# HSM_HSM_SHA_CE004000h register map
Vendor: Texas Instruments
Peripheral module from a debugger description file (folder AM263X).
Registers are 32-bit, read-write, reset values left out (the file's numbers can be read two ways) unless marked. A register's access mark holds for its fields unless they carry their own. Offsets are as the file gives them; lines under a group give offsets from that group; [hi:lo] are bit positions; {n}, {i} and the like mark numbered series; 'fields as' and 'values as' point back to an identical list; <NAME> marks a mode.

## HSM_SHA
0x00 HSM_SHA_S_ODIGEST_A — WRITE: Outer Digest [127:96] for MD5 [159:128] for SHA-1 [255:224] for SHA-2 / HMAC Key [31:0] for HMAC key proc READ: Outer Digest [127:96] for MD5 [159:128] for SHA-1 [255:224] for SHA-2
  [31:0] DATA
0x04 HSM_SHA_S_ODIGEST_B — WRITE: Outer Digest [95:64] for MD5 [127:96] for SHA-1 [223:192] for SHA-2 / HMAC Key [63:32] for HMAC key proc READ: Outer Digest [95:64] for MD5 [127:96] for SHA-1 [223:192] for SHA-2
  [31:0] DATA
0x08 HSM_SHA_S_ODIGEST_C — WRITE: Outer Digest [63:32] for MD5 [95:64] for SHA-1 [191:160] for SHA-2 / HMAC Key [95:64] for HMAC key proc READ: Outer Digest [63:32] for MD5 [95:64] for SHA-1 [191:160] for SHA-2
  [31:0] DATA
0x0C HSM_SHA_S_ODIGEST_D — WRITE: Outer Digest [31:0] for MD5 [63:31] for SHA-1 [159:128] for SHA-2 / HMAC Key [127:96] for HMAC key proc READ: Outer Digest [31:0] for MD5 [63:32] for SHA-1 [159:128] for SHA-2
  [31:0] DATA
0x10 HSM_SHA_S_ODIGEST_E — WRITE: Outer Digest [31:0] for SHA-1 [127:96] for SHA-2 / HMAC Key [159:128] for HMAC key proc READ: Outer Digest [31:0] for SHA-1 [127:96] for SHA-2
  [31:0] DATA
0x14 HSM_SHA_S_ODIGEST_F — WRITE: Outer Digest [95:64] for SHA-2 / HMAC Key [191:160] for HMAC key proc READ: Outer Digest [95:64] for SHA-2
  [31:0] DATA
0x18 HSM_SHA_S_ODIGEST_G — WRITE: Outer Digest [63:32] for SHA-2 / HMAC Key [223:192] for HMAC key proc READ: Outer Digest [63:32] for SHA-2
  [31:0] DATA
0x1C HSM_SHA_S_ODIGEST_H — WRITE: Outer Digest [31:0] for SHA-2 / HMAC Key [255:224] for HMAC key proc READ: Outer Digest [31:0] for SHA-2
  [31:0] DATA
0x20 HSM_SHA_S_IDIGEST_A — WRITE: Inner / Initial Digest [127:96] for MD5 [159:128] for SHA-1 [255:224] for SHA-2 / HMAC Key [287:256] for HMAC key proc READ: Intermediate / Inner Digest [127:96] for MD5 [159:128] for SHA-1 [255:224] for SHA-2 / Result Digest/MAC [127:96] for MD5 [159:128] for SHA-1 [223:192] for SHA-2 224 [255:224] for SHA-2 256.
  [31:0] DATA
0x24 HSM_SHA_S_IDIGEST_B — WRITE: Inner / Initial Digest [95:64] for MD5 [127:96] for SHA-1 [223:192] for SHA-2 / HMAC Key [319:288] for HMAC key proc READ: Intermediate / Inner Digest [95:64] for MD5 [127:96] for SHA-1 [223:192] for SHA-2 / Result Digest/MAC [95:64] for MD5 [127:96] for SHA-1 [191:160] for SHA-2 224 [223:192] for SHA-2 256.
  [31:0] DATA
0x28 HSM_SHA_S_IDIGEST_C — WRITE: Inner / Initial Digest [63:32] for MD5 [95:64] for SHA-1 [191:160] for SHA- 2 / HMAC Key [351:320] for HMAC key proc READ: Intermediate / Inner Digest [63:32] for MD5 [95:64] for SHA-1 [191:160] for SHA-2 / Result Digest/MAC [63:32] for MD5 [95:64] for SHA-1 [159:128] for SHA-2 224 [191:160] for SHA-2 256.
  [31:0] DATA
0x2C HSM_SHA_S_IDIGEST_D — WRITE: Inner / Initial Digest [31:0] for MD5 [63:32] for SHA-1 [159:128] for SHA-2 / HMAC Key [383:352] for HMAC key proc READ: Intermediate / Inner Digest [31:0] for MD5 [63:32] for SHA-1 [159:128] for SHA-2 / Result Digest/MAC [31:0] for MD5 [63:32] for SHA-1 [127:96] for SHA-2 224 [159:128] for SHA-2 256.
  [31:0] DATA
0x30 HSM_SHA_S_IDIGEST_E — WRITE: Inner / Initial Digest [31:0] for SHA-1 [127:96] for SHA-2 / HMAC Key [415:384] for HMAC key proc READ: Intermediate / Inner Digest [31:0] for SHA-1 [127:96] for SHA-2 / Result Digest/MAC [31:0] for SHA-1 [95:64] for SHA-2 224 [127:96] for SHA-2 256.
  [31:0] DATA
0x34 HSM_SHA_S_IDIGEST_F — WRITE: Inner / Initial Digest [95:64] for SHA-2 / HMAC Key [447:416] for HMAC key proc READ: Intermediate / Inner Digest [95:64] for SHA-2 / Result Digest/MAC [63:32] for SHA-2 224 [95:64] for SHA-2 256.
  [31:0] DATA
0x38 HSM_SHA_S_IDIGEST_G — WRITE: Inner / Initial Digest [63:32] for SHA-2 / HMAC Key [479:448] for HMAC key proc READ: Intermediate / Inner Digest [63:32] for SHA-2 / Result Digest/MAC [31:0] for SHA-2 224 [63:32] for SHA-2 256.
  [31:0] DATA
0x3C HSM_SHA_S_IDIGEST_H — WRITE: Inner / Initial Digest [31:0] for SHA-2 / HMAC Key [511:480] for HMAC key proc READ: Intermediate / Inner Digest [31:0] for SHA-2 / Result Digest/MAC [31:0] for SHA-2 256.
  [31:0] DATA
0x40 HSM_SHA_S_DIGEST_COUNT — WRITE: Initial Digest Count ([31:6] only [5:0] assumed 0) READ: Result / IntermediateDigest Count The initial digest byte count for hash/HMAC continue operations (HMAC Key Processing = 0 and Use Algorithm Constants = 0) on the Secure World must be written to this register prior to starting the operation by writing to S_HASH_MODE. When either HMAC Key Processing is 1 or Use Algorithm Constants is 1 this register does not need to be written it will be overwritten with 64 (1 hash block of key XOR ipad) or 0 respectively automatically. When starting a HMAC operation from pre-computes (HMAC Key Processing is 0) then the value 64 must be written here to compensate for the appended key XOR ipad block. Note that the value written should always be a 64 byte multiple the lower 6 bits written are ignored. The updated digest byte count (initial digest byte count + bytes processed) can be read from this register when the status register indicates that the operation is done or suspended due to a context switch request or when a Secure World context out DMA is requested. In Advanced DMA mode when not suspended with a partial result reading the SHA_P_DIGEST_COUNT register triggers the Hash/HMAC Engine to start the next context input DMA. Therefore reading the SHA_P_DIGEST_COUNT register should always be the last context-read action if not suspended with a partial result (i.e. PartHashReady interrupt not pending).
  [31:0] DATA
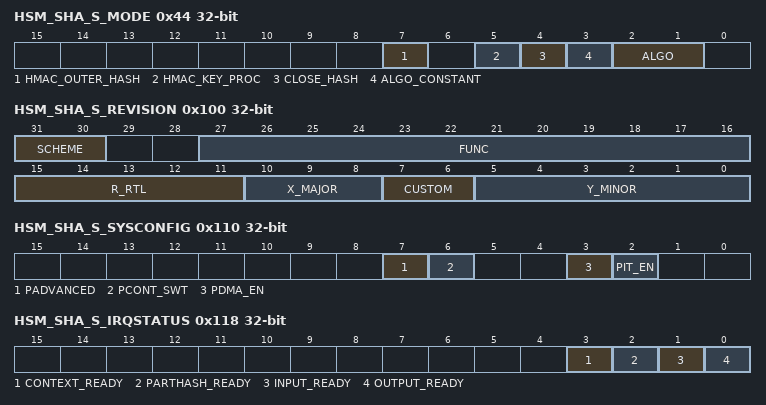
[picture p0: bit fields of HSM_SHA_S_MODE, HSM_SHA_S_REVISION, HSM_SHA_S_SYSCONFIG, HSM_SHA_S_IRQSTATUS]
0x44 HSM_SHA_S_MODE — Register SHA_MODE.
  [7] HMAC_OUTER_HASH — The HMAC Outer Hash is performed on the hash digest when the inner hash hash finished [block length exhausted and final hash performed if close_hash is 1]. This bit should normally be set together with close_hash to finish the inner hash first or Block Length should be zero [HMAC continue with the just outer hash to be done]. Auto cleared internally when outer hash performed. 0 No operation 1 hmac processing
  [5] HMAC_KEY_PROC — Performs HMAC key processing on the 512 bit HMAC key loaded into the SHA_P_IDIGEST_{A to H} and SHA_P_ODIGEST_{A to H} register block. Once HMAC key processing is finished this bit is automatically cleared and the resulting Inner and Outer digest is available from SHA_P_IDIGEST_{A to H} and SHA_P_ODIGEST_{A to H} respectively after which regular hash processing [using SHA_P_IDIGEST_{A to H} as initial digest] will commence until the Block Length is exhausted. 0 No operation. 1 Hmac processing.
  [4] CLOSE_HASH — Performs the padding the hash/HMAC will be 'closed' at the end of the block as per MD5/SHA-1/SHA-2 specification [i.e. appropriate padding is added] or no padding is done allowing the hash to be continued later. However if the hash/HMAC is not closed then the Block Length MUST be a multiple of 64 bytes to ensure correct operation. Auto cleared internally when hash closed. 0 No padding hash computation can be contimued. 1 Last packet will be padded.
  [3] ALGO_CONSTANT — The initial digest register will be overwritten with the algorithm constants for the selected algorithm when hashing and the initial digest count register will be reset to 0. This will start a normal hash operation. When continuing an existing hash or when performing an HMAC operation this register must be set to 0 and the intermediate/inner digest or HMAC key and digest count need to be written to the context input registers prior to Writing SHA_P_MODE. Auto cleared internally after first block processed. 0 Use pre-calculated digest [from an other operation] 1 Use constants of the selected algo.
  [2:1] ALGO — These bits select the hash algorithm to be used for processing: 0 md5_128 algorithm 0x1 sha1_160 algorithm 0x2 sha2_224 algorithm 0x3 sha2_256 algorithm
0x48 HSM_SHA_S_LENGTH — WRITE: Block Length / Remaining Byte Count (bytes) READ: Remaining Byte Count. The value programmed MUST be a 64-byte multiple if Close Hash is set to 0. This register is also the trigger to start processing: once this register is written the core will commence requesting input data via DMA or IRQ (if programmed length > 0) and start processing. The remaining byte count for the active operation can be read from this register when the interrupt status register indicates that the operation is suspended due to a context switch request.
  [31:0] DATA
{0x80+4i} HSM_SHA_S_DATA{i}_IN wo (i=0..9) — Data input message {i}
  [31:0] DATA{i}_IN — data
{0x80+4i} HSM_SHA_S_DATA{i}_IN wo (i=10..15) — Data input message {i}.
  [31:0] DATA{i}_IN — data
0x100 HSM_SHA_S_REVISION ro — Register SHA_REV.
  [31:30] SCHEME — Used to distinguish between old scheme and current. Read 0 Legacy ASP or WTBU scheme Read 0x1 Highlander 0.8 scheme
  [27:16] FUNC — Function indicates a software compatible module family. If there is no level of software compatibility a new Func number [and hence REVISION] should be assigned.
  [15:11] R_RTL — RTL Version [R] maintained by IP design owner. RTL follows a numbering such as X.Y.R.Z which are explained in this table. R changes ONLY when: [1] PDS uploads occur which may have been due to spec changes [2] Bug fixes occur [3] Resets to '0' when X or Y changes. Design team has an internal 'Z' [customer invisible] number which increments on every drop that happens due to DV and RTL updates. Z resets to 0 when R increments.
  [10:8] X_MAJOR — Major Revision [X] maintained by IP specification owner. X changes ONLY when: [1] There is a major feature addition. An example would be adding Master Mode to Utopia Level2. The Func field [or Class/Type in old PID format] will remain the same. X does NOT change due to: [1] Bug fixes [2] Change in feature parameters.
  [7:6] CUSTOM — Indicates a special version for a particular device. Consequence of use may avoid use of standard Chip Support Library [CSL] / Drivers. Read 0 Non custom [standard] revision
  [5:0] Y_MINOR — Minor Revision [Y] maintained by IP specification owner. Y changes ONLY when: [1] Features are scaled [up or down]. Flexibility exists in that this feature scalability may either be represented in the Y change or a specific register in the IP that indicates which features are exactly available. [2] When feature creeps from Is-Not list to Is list. But this may not be the case once it sees silicon; in which case X will change. Y does NOT change due to: [1] Bug fixes [2] Typos or clarifications [3] major functional/feature change/addition/deletion. Instead these changes may be reflected via R S X as applicable. Spec owner maintains a customer-invisible number 'S' which changes due to: [1] Typos/clarifications [2] Bug documentation. Note that this bug is not due to a spec change but due to implementation. Nevertheless the spec tracks the IP bugs. An RTL release [say for silicon PG1.1] that occurs due to bug fix should document the corresponding spec number [X.Y.S] in its release notes.
0x110 HSM_SHA_S_SYSCONFIG — Register SHA_SYSCONFIG.
  [7] PADVANCED — If set to 1 Advanced mode is enabled for the Secure World. If set to 0 Legacy mode is enabled for the Secure World.
  [6] PCONT_SWT — Finish all pending data and context DMA input requests [but will not assert any new requests] finish processing all data in the module and provide a saved context [partial hash result updated digest count remaining length updated mode information where applicable] for the last operation that was interrupted so that it can be resumed later.
  [3] PDMA_EN — Enable dma Read 0 Interrupt disenabled Read 1 Interrupt enabled
  [2] PIT_EN — Enable interrupt Read 0 Interrupt disenabled Read 1 Interrupt enabled
0x114 HSM_SHA_S_SYSSTATUS — Register SHA_SYSSTATUS.
  [0] RESETDONE — data
0x118 HSM_SHA_S_IRQSTATUS ro — Register SHA_IRQSTATUS.
  [3] CONTEXT_READY — Indicates that the secure side context input registers are available for a new context for the next packet to be processed.
  [2] PARTHASH_READY — After a secure side context switch request this bit will read as 1 indicating that the saved context is available from the secure side context output registers. Note that if the context switch request coincides with a final hash [when hashing] or an outer hash [when doing HMAC] that PartHashReady will not become active but a regular Output Ready will occur instead [indicating that the result is final and therefore no continuation is required].
  [1] INPUT_READY — Indicates that the secure side data FIFO is ready to receive the next 64 byte data block.
  [0] OUTPUT_READY — Indicates that a [partial] result or saved context is available from the secure side context output registers.
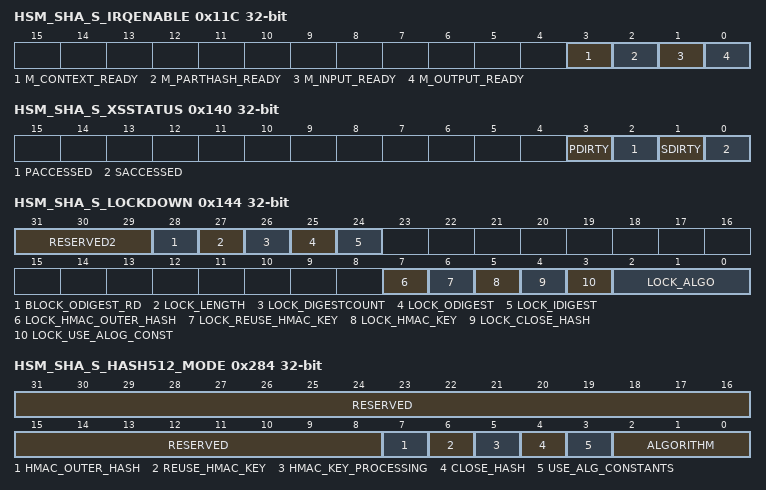
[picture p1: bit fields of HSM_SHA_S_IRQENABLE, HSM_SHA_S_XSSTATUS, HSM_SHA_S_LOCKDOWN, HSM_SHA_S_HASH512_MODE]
0x11C HSM_SHA_S_IRQENABLE — Register SHA_IRQENABLE. The SHA_P_IRQENABLE register contains an enable bit for each unique interrupt for the public side. An interrupt is enabled when both the global enable in SHA_P_SYSCONFIG (PIT_en) and the bit in this register are both set to 1. An interrupt that is enabled is propagated to the SINTREQUEST_P output. Please note that the dedicated partial hash output (SINTREQUEST_PART_P) is not affected by this register it is only affected by the global enable SHA_P_SYSCONFIG (PIT_en).
  [3] M_CONTEXT_READY — mask for context ready
  [2] M_PARTHASH_READY — mask for partial hash
  [1] M_INPUT_READY — mask for input_ready
  [0] M_OUTPUT_READY — mask for output_ready
0x140 HSM_SHA_S_XSSTATUS — Secure/Private world Register read/write status.
  [3] PDIRTY — This bit is set to 1 by the module if any of the Public World registers is written. It can be cleared by the host by Writing a 1 in this location.
  [2] PACCESSED — This bit is set to 1 by the module if any of the Public World registers is read. It can be cleared by the host by Writing a 1 in this location
  [1] SDIRTY — This bit is set to 1 by the module if any of the Secure World registers is written. It can be cleared by the host by Writing a 1 in this location.
  [0] SACCESSED — This bit is set to 1 by the module if any of the Secure World registers is read. It can be cleared by the host by Writing a 1 in this location.
0x144 HSM_SHA_S_LOCKDOWN access per field — Use this Register to lock the algorithm preventing further use.
  [31:29] RESERVED2 ro — These bits should be written with zeroes and ignored on reads.
  [28] BLOCK_ODIGEST_RD rw — This makes the P_HASH_ODIGEST_A through P_HASH_ODIGEST_H write-only, further protecting the HMAC key from being read by Public World software. Note: setting this bit also makes HMAC continue operations impossible!
  [27] LOCK_LENGTH rw — When this bit is set, the P_HASH_LENGTH register cannot be overwritten. This prevents Public World software from truncating or extending the block to be hashed or starting hash/HMAC operations by itself.
  [26] LOCK_DIGESTCOUNT rw — When this bit is set, the P_HASH_DIGEST_COUNT register cannot be overwritten. This, in combination with bits 3 and 24 prevents the Public World software from adding data at the front of the block to be hashed.
  [25] LOCK_ODIGEST rw — When this bit is set, the P_HASH_ODIGEST_A through P_HASH_ODIGEST_H registers cannot be overwritten. This prevents Public World software from loading a weak and/or known HMAC key or an outer digest value.
  [24] LOCK_IDIGEST rw — When this bit is set, the P_HASH_IDIGEST_A through P_HASH_IDIGEST_H registers cannot be overwritten. This prevents Public World software from loading a weak and/or known key or an initial digest value
  [7] LOCK_HMAC_OUTER_HASH rw — When this bit is set, HMAC Outer Hash bit in P_HASH_MODE cannot be modified.This prevents Public World software from bypassing the HMAC closure by clearing the corresponding mode bit during processing.
  [6] LOCK_REUSE_HMAC_KEY rw — When this bit is set, the Reuse HMAC Key bit in P_HASH_MODE cannot be modified
  [5] LOCK_HMAC_KEY rw — When this bit is set, the HMAC Key Preprocessing bit in P_HASH_MODE cannot be modified. This prevents Public World software from bypassing the HMAC key preprocessing step and using the key data directly
  [4] LOCK_CLOSE_HASH rw — When this bit is set, the Close Hash bit in P_HASH_MODE cannot be modified.This prevents Public World software from bypassing the hash closure by clearing the corresponding mode bit during processing.
  [3] LOCK_USE_ALOG_CONST rw — When this bit is set, the Use Alg Constants bit in P_HASH_MODE cannot be modified. This e.g. prevents Public World software from switching to [known!] algorithm constants instead of the [secret key based?] loaded & locked initial digest.
  [2:0] LOCK_ALGO rw — When either lock bit is set, the corresponding Algorithm bit in P_HASH_MODE cannot be modified. This locks the algorithm preventing further use.
0x200 HSM_SHA_S_HASH512_ODIGEST_A — Public World Outer SHA-512 Digest .
  [31:0] ODIGEST_A — W: Outer Digest [511:480] for SHA-384 and SHA-512 / SHA512_HMAC Key [31:0] for HMAC key procR: Outer Digest [511:480] for SHA-384 and SHA-512
0x204 HSM_SHA_S_HASH512_ODIGEST_B — Public World Outer SHA-512 Digest .
  [31:0] ODIGEST_B — W: Outer Digest [479:448] for SHA-384 and SHA-512 / SHA512_HMAC Key [63:32] for HMAC key procR: Outer Digest [479:448] for SHA-384 and SHA-512
0x208 HSM_SHA_S_HASH512_ODIGEST_C — Public World Outer SHA-512 Digest .
  [31:0] ODIGEST_C — W: Outer Digest [447:416] for SHA-384 and SHA-512 / SHA512_HMAC Key [95:64] for HMAC key procR: Outer Digest [447:416] for SHA-384 and SHA-512
0x20C HSM_SHA_S_HASH512_ODIGEST_D — Public World Outer SHA-512 Digest .
  [31:0] ODIGEST_D — W: Outer Digest [415:384] for SHA-384 and SHA-512 / SHA512_HMAC Key [127:96] for HMAC key procR: Outer Digest [415:384] for SHA-384 and SHA-512
0x210 HSM_SHA_S_HASH512_ODIGEST_E — Public World Outer SHA-512 Digest .
  [31:0] ODIGEST_E — W: Outer Digest [383:352] for SHA-384 and SHA-512 / SHA512_HMAC Key [159:128] for HMAC key procR: Outer Digest [383:352] for SHA-384 and SHA-512
0x214 HSM_SHA_S_HASH512_ODIGEST_F — Public World Outer SHA-512 Digest .
  [31:0] ODIGEST_F — W: Outer Digest [351:320] for SHA-384 and SHA-512 / SHA512_HMAC Key [191:160] for HMAC key procR: Outer Digest [351:320] for SHA-384 and SHA-512
0x218 HSM_SHA_S_HASH512_ODIGEST_G — Public World Outer SHA-512 Digest .
  [31:0] ODIGEST_G — W: Outer Digest [319:288] for SHA-384 and SHA-512 / SHA512_HMAC Key [223:192] for HMAC key procR: Outer Digest [319:288] for SHA-384 and SHA-512
0x21C HSM_SHA_S_HASH512_ODIGEST_H — Public World Outer SHA-512 Digest .
  [31:0] ODIGEST_H — W: Outer Digest [287:256] for SHA-384 and SHA-512 / SHA512_HMAC Key [255:244] for HMAC key procR: Outer Digest [287:256] for SHA-384 and SHA-512
0x220 HSM_SHA_S_HASH512_ODIGEST_I — Public World Outer SHA-512 Digest .
  [31:0] ODIGEST_I — W: Outer Digest [255:224] for SHA-384 and SHA-512 / SHA512_HMAC Key [287:256] for HMAC key procR: Outer Digest [255:224] for SHA-384 and SHA-512
0x224 HSM_SHA_S_HASH512_ODIGEST_J — Public World Outer SHA-512 Digest .
  [31:0] ODIGEST_J — W: Outer Digest [223:192] for SHA-384 and SHA-512 / SHA512_HMAC Key [319:288] for HMAC key procR: Outer Digest [223:129] for SHA-384 and SHA-512
0x228 HSM_SHA_S_HASH512_ODIGEST_K — Public World Outer SHA-512 Digest .
  [31:0] ODIGEST_K — W: Outer Digest [191:160] for SHA-384 and SHA-512 / SHA512_HMAC Key [351:320] for HMAC key procR: Outer Digest [191:160] for SHA-384 and SHA-512
0x22C HSM_SHA_S_HASH512_ODIGEST_L — Public World Outer SHA-512 Digest .
  [31:0] ODIGEST_L — W: Outer Digest [159:128] for SHA-384 and SHA-512 / SHA512_HMAC Key [383:352] for HMAC key procR: Outer Digest [159:128] for SHA-384 and SHA-512
0x230 HSM_SHA_S_HASH512_ODIGEST_M — Public World Outer SHA-512 Digest .
  [31:0] ODIGEST_M — W: Outer Digest [128:96] for SHA-384 and SHA-512 / SHA512_HMAC Key [415:384] for HMAC key procR: Outer Digest [128:96] for SHA-384 and SHA-512
0x234 HSM_SHA_S_HASH512_ODIGEST_N — Public World Outer SHA-512 Digest .
  [31:0] ODIGEST_N — W: Outer Digest [95:64] for SHA-384 and SHA-512 / SHA512_HMAC Key [447:416] for HMAC key procR: Outer Digest [95:64] for SHA-384 and SHA-512
0x238 HSM_SHA_S_HASH512_ODIGEST_O — Public World Outer SHA-512 Digest .
  [31:0] ODIGEST_O — W: Outer Digest [63:32] for SHA-384 and SHA-512 / SHA512_HMAC Key [479:448] for HMAC key procR: Outer Digest [63:32] for SHA-384 and SHA-512
0x23C HSM_SHA_S_HASH512_ODIGEST_P — Public World Outer SHA-512 Digest .
  [31:0] ODIGEST_P — W: Outer Digest [31:0] for SHA-384 and SHA-512 / SHA512_HMAC Key [511:480] for HMAC key procR: Outer Digest [31:0] for SHA-384 and SHA-512
0x240 HSM_SHA_S_HASH512_IDIGEST_A — Public World Inner SHA-512 Digest .
  [31:0] IDIGEST_A — W: Inner / Initial Digest [383:352] for SHA-384 and [511:480] for SHA-512 / SHA512_HMAC Key [543:512] for HMAC key procR: Intermediate / Inner Digest Digest [383:352] for SHA-384 and [511:480] for SHA-512Result Digest/MAC Digest [383:352] for SHA-384 and [511:480] for SHA-512
0x244 HSM_SHA_S_HASH512_IDIGEST_B — Public World Inner SHA-512 Digest .
  [31:0] IDIGEST_B — W: Inner / Initial Digest [531:320] for SHA-384 and [479:448] for SHA-512 / SHA512_HMAC Key [543:512] for HMAC key procR: Intermediate / Inner Digest Digest Digest [531:320] for SHA-384 and [479:448] for SHA-512Result Digest/MAC Digest Digest [531:320] for SHA-384 and [479:448] for SHA-512
0x248 HSM_SHA_S_HASH512_IDIGEST_C — Public World Inner SHA-512 Digest .
  [31:0] IDIGEST_C — W: Inner / Initial Digest [319:288] for SHA-384 and [416:447] for SHA-512 / SHA512_HMAC Key [543:512] for HMAC key procR: Intermediate / Inner Digest Digest Digest [319:288] for SHA-384 and [416:447] for SHA-512Result Digest/MAC Digest Digest [319:288] for SHA-384 and [416:447] for SHA-512
0x24C HSM_SHA_S_HASH512_IDIGEST_D — Public World Inner SHA-512 Digest .
  [31:0] IDIGEST_D — W: Inner / Initial Digest [287:256] for SHA-384 and [415:384] for SHA-512 / SHA512_HMAC Key [639:608] for HMAC key procR: Intermediate / Inner Digest [287:256] for SHA-384 and [415:384] for SHA-512Result Digest/MAC Digest Digest [287:256] for SHA-384 and [415:384] for SHA-512
0x250 HSM_SHA_S_HASH512_IDIGEST_E — Public World Inner SHA-512 Digest .
  [31:0] IDIGEST_E — W: Inner / Initial Digest [255:224] for SHA-384 and [383:362] for SHA-512 / SHA512_HMAC Key [671:640] for HMAC key procR: Intermediate / Inner Digest [255:224] for SHA-384 and [383:362] for SHA-512Result Digest/MAC Digest Digest [255:224] for SHA-384 and [383:362] for SHA-512
0x254 HSM_SHA_S_HASH512_IDIGEST_F — Public World Inner SHA-512 Digest .
  [31:0] IDIGEST_F — W: Inner / Initial Digest [223:192] for SHA-384 and [351:320] for SHA-512 / SHA512_HMAC Key [703:672] for HMAC key procR: Intermediate / Inner Digest [223:192] for SHA-384 and [351:320] for SHA-512Result Digest/MAC Digest Digest [223:192] for SHA-384 and [351:320] for SHA-512
0x258 HSM_SHA_S_HASH512_IDIGEST_G — Public World Inner SHA-512 Digest .
  [31:0] IDIGEST_G — W: Inner / Initial Digest [191:160] for SHA-384 and [319:288] for SHA-512 / SHA512_HMAC Key [735:704] for HMAC key procR: Intermediate / Inner Digest [191:160] for SHA-384 and [319:288] for SHA-512Result Digest/MAC Digest Digest [191:160] for SHA-384 and [319:288] for SHA-512
0x25C HSM_SHA_S_HASH512_IDIGEST_H — Public World Inner SHA-512 Digest .
  [31:0] IDIGEST_H — W: Inner / Initial Digest [159:128] for SHA-384 and [287:256] for SHA-512 / SHA512_HMAC Key [767:736] for HMAC key procR: Intermediate / Inner Digest [159:128] for SHA-384 and [287:256] for SHA-512Result Digest/MAC Digest Digest [159:128] for SHA-384 and [287:256] for SHA-512
0x260 HSM_SHA_S_HASH512_IDIGEST_I — Public World Inner SHA-512 Digest .
  [31:0] IDIGEST_I — W: Inner / Initial Digest [127:96] for SHA-384 and [255:224] for SHA-512 / SHA512_HMAC Key [799:768] for HMAC key procR: Intermediate / Inner Digest [127:96] for SHA-384 and [255:224] for SHA-512Result Digest/MAC Digest Digest [127:96] for SHA-384 and [255:224] for SHA-512
0x264 HSM_SHA_S_HASH512_IDIGEST_J — Public World Inner SHA-512 Digest .
  [31:0] IDIGEST_J — W: Inner / Initial Digest [95:64] for SHA-384 and [223:192] for SHA-512 / SHA512_HMAC Key [831:800] for HMAC key procR: Intermediate / Inner Digest [95:64] for SHA-384 and [223:192] for SHA-512Result Digest/MAC Digest Digest [95:64] for SHA-384 and [223:192] for SHA-512
0x268 HSM_SHA_S_HASH512_IDIGEST_K — Public World Inner SHA-512 Digest .
  [31:0] IDIGEST_K — W: Inner / Initial Digest [63:32] for SHA-384 and [191:160] for SHA-512 / SHA512_HMAC Key [863:832] for HMAC key procR: Intermediate / Inner Digest [63:32] for SHA-384 and [191:160] for SHA-512Result Digest/MAC Digest Digest [63:32] for SHA-384 and [191:160] for SHA-512
0x26C HSM_SHA_S_HASH512_IDIGEST_L — Public World Inner SHA-512 Digest .
  [31:0] IDIGEST_L — W: Inner / Initial Digest [31:0] for SHA-384 and [159:128] for SHA-512 / SHA512_HMAC Key [895:864] for HMAC key procR: Intermediate / Inner Digest [31:0] for SHA-384 and [159:128] for SHA-512Result Digest/MAC Digest Digest [31:0] for SHA-384 and [159:128] for SHA-512
0x270 HSM_SHA_S_HASH512_IDIGEST_M — Public World Inner SHA-512 Digest .
  [31:0] IDIGEST_M — W: Inner / Initial Digest [127:96] for SHA-512 / SHA512_HMAC Key [927:896] for HMAC key procR: Intermediate / Inner Digest [127:96] for SHA-512Result Digest/MAC Digest Digest [127:96] for SHA-512
0x274 HSM_SHA_S_HASH512_IDIGEST_N — Public World Inner SHA-512 Digest .
  [31:0] IDIGEST_N — W: Inner / Initial Digest [95:64] for SHA-512 / SHA512_HMAC Key [959:928] for HMAC key procR: Intermediate / Inner Digest [95:64] for SHA-512Result Digest/MAC Digest Digest [95:64] for SHA-512
0x278 HSM_SHA_S_HASH512_IDIGEST_O — Public World Inner SHA-512 Digest .
  [31:0] IDIGEST_O — W: Inner / Initial Digest [63:32] for SHA-512 / SHA512_HMAC Key [991:960] for HMAC key procR: Intermediate / Inner Digest [63:32] for SHA-512Result Digest/MAC Digest Digest [63:32] for SHA-512
0x27C HSM_SHA_S_HASH512_IDIGEST_P — Public World Inner SHA-512 Digest .
  [31:0] IDIGEST_P — W: Inner / Initial Digest [31:0] for SHA-512 / SHA512_HMAC Key 1023992] for HMAC key procR: Intermediate / Inner Digest [31:0] for SHA-512Result Digest/MAC Digest Digest [31:0] for SHA-512
0x280 HSM_SHA_S_HASH512_DIGEST_COUNT — Public World SHA-512 Digest Count .
  [31:0] DIGEST_COUNT — W: Initial Digest Count [[31:7] only, [6:0] assumed 0]R: Result / IntermediateDigest Count
0x284 HSM_SHA_S_HASH512_MODE access per field — Public World SHA-512 Hash Mode.
  [31:8] RESERVED ro — These bits should be written with zeroes and ignored on reads.
  [7] HMAC_OUTER_HASH rw — If set to 1, the HMAC Outer Hash is performed on the hash digest when the inner hash hash finished [block length exhausted and final hash performed if Close Hash is 1].This bit should normally be set together with Close Hash to finish the inner hash first, or Block Length should be zero [HMAC continue with the just outer hash to be done].Auto cleared internally when outer hash performed.
  [6] REUSE_HMAC_KEY rw — If set to 1, an HMAC operation is started using the HMAC key that was loaded at the time HMAC Key Processing was last performed, provided that the P_HASH512_ODIGEST registers have not been overwritten since. This makes it possible to authenticate multiple blocks using the HMAC key without actually having to reload the key.Note that P_HASH512_DIGEST_COUNT is forced to 128 to indicate that the 128 byte key XOR ipad block has been processed first. This bit should not be set together with bit 5.
  [5] HMAC_KEY_PROCESSING rw — If set to 1, the hash core will perform HMAC key processing on the HMAC key [with block size length] loaded into the P_HASH512_IDIGEST:P_HASH512_ODIGEST register block. Once HMAC key processing is finished, this bit is automatically cleared and the resulting Inner and Outer digest is available from P_HASH512_IDIGEST and P_HASH512_ODIGEST respectively, after which regular hash processing [using P_HASH512_IDIGEST as initial digest] will commence until the Block Length is exhausted. Note that P_HASH_DIGEST512_COUNT is forced to 128 to indicate that the 128 byte key XOR ipad block has been processed first.
  [4] CLOSE_HASH rw — If set to 1, then the hash/HMAC will be 'closed' at the end of the block, as per MD5/SHA-1/SHA-2 specification [i.e. appropriate padding is added]. If set to 0, then the hash/HMAC will not be closed and can be continued later. However, if the hash/HMAC is not closed then the Block Length MUST be a multiple of the hash bloc k size to ensure correct operation. Auto cleared internally when hash close operation starts.
  [3] USE_ALG_CONSTANTS rw — If set to 1, the initial digest register will be overwritten with the algorithm constants for the selected algorithm when hashing and the initial digest count register will be reset to 0. This will start a normal hash operation. When continuing an existing hash or when performing an HMAC operation, this register must be set to 0 and the intermediate/inner digest or HMAC key and digest count need to be written to the context input registers prior to Writing P_HASH512_MODE.Auto cleared internally after first block processed.
  [2:0] ALGORITHM rw — These bits select the hash algorithm to be used for processing:000 - MD5010 - SHA-1100 - SHA-224110 - SHA-256001 - SHA-384011 - SHA-512
0x288 HSM_SHA_S_HASH512_LENGTH — Public World SHA-512 Block Length .
  [31:0] LENGTH — W: Block Length / Remaining Byte Count [bytes]R: Remaining Byte Count
0x1000 HSM_SHA_P_ODIGEST_A — WRITE: Outer Digest [127:96] for MD5 [159:128] for SHA-1 [255:224] for SHA-2 / HMAC Key [31:0] for HMAC key proc READ: Outer Digest [127:96] for MD5 [159:128] for SHA-1 [255:224] for SHA-2
  [31:0] DATA
0x1004 HSM_SHA_P_ODIGEST_B — WRITE: Outer Digest [95:64] for MD5 [127:96] for SHA-1 [223:192] for SHA-2 / HMAC Key [63:32] for HMAC key proc READ: Outer Digest [95:64] for MD5 [127:96] for SHA-1 [223:192] for SHA-2
  [31:0] DATA
0x1008 HSM_SHA_P_ODIGEST_C — WRITE: Outer Digest [63:32] for MD5 [95:64] for SHA-1 [191:160] for SHA-2 / HMAC Key [95:64] for HMAC key proc READ: Outer Digest [63:32] for MD5 [95:64] for SHA-1 [191:160] for SHA-2
  [31:0] DATA
0x100C HSM_SHA_P_ODIGEST_D — WRITE: Outer Digest [31:0] for MD5 [63:31] for SHA-1 [159:128] for SHA-2 / HMAC Key [127:96] for HMAC key proc READ: Outer Digest [31:0] for MD5 [63:32] for SHA-1 [159:128] for SHA-2
  [31:0] DATA
0x1010 HSM_SHA_P_ODIGEST_E — WRITE: Outer Digest [31:0] for SHA-1 [127:96] for SHA-2 / HMAC Key [159:128] for HMAC key proc READ: Outer Digest [31:0] for SHA-1 [127:96] for SHA-2
  [31:0] DATA
0x1014 HSM_SHA_P_ODIGEST_F — WRITE: Outer Digest [95:64] for SHA-2 / HMAC Key [191:160] for HMAC key proc READ: Outer Digest [95:64] for SHA-2
  [31:0] DATA
0x1018 HSM_SHA_P_ODIGEST_G — WRITE: Outer Digest [63:32] for SHA-2 / HMAC Key [223:192] for HMAC key proc READ: Outer Digest [63:32] for SHA-2
  [31:0] DATA
0x101C HSM_SHA_P_ODIGEST_H — WRITE: Outer Digest [31:0] for SHA-2 / HMAC Key [255:224] for HMAC key proc READ: Outer Digest [31:0] for SHA-2
  [31:0] DATA
0x1020 HSM_SHA_P_IDIGEST_A — WRITE: Inner / Initial Digest [127:96] for MD5 [159:128] for SHA-1 [255:224] for SHA-2 / HMAC Key [287:256] for HMAC key proc READ: Intermediate / Inner Digest [127:96] for MD5 [159:128] for SHA-1 [255:224] for SHA-2 / Result Digest/MAC [127:96] for MD5 [159:128] for SHA-1 [223:192] for SHA-2 224 [255:224] for SHA-2 256.
  [31:0] DATA
0x1024 HSM_SHA_P_IDIGEST_B — WRITE: Inner / Initial Digest [95:64] for MD5 [127:96] for SHA-1 [223:192] for SHA-2 / HMAC Key [319:288] for HMAC key proc READ: Intermediate / Inner Digest [95:64] for MD5 [127:96] for SHA-1 [223:192] for SHA-2 / Result Digest/MAC [95:64] for MD5 [127:96] for SHA-1 [191:160] for SHA-2 224 [223:192] for SHA-2 256.
  [31:0] DATA
0x1028 HSM_SHA_P_IDIGEST_C — WRITE: Inner / Initial Digest [63:32] for MD5 [95:64] for SHA-1 [191:160] for SHA- 2 / HMAC Key [351:320] for HMAC key proc READ: Intermediate / Inner Digest [63:32] for MD5 [95:64] for SHA-1 [191:160] for SHA-2 / Result Digest/MAC [63:32] for MD5 [95:64] for SHA-1 [159:128] for SHA-2 224 [191:160] for SHA-2 256.
  [31:0] DATA
0x102C HSM_SHA_P_IDIGEST_D — WRITE: Inner / Initial Digest [31:0] for MD5 [63:32] for SHA-1 [159:128] for SHA-2 / HMAC Key [383:352] for HMAC key proc READ: Intermediate / Inner Digest [31:0] for MD5 [63:32] for SHA-1 [159:128] for SHA-2 / Result Digest/MAC [31:0] for MD5 [63:32] for SHA-1 [127:96] for SHA-2 224 [159:128] for SHA-2 256.
  [31:0] DATA
0x1030 HSM_SHA_P_IDIGEST_E — WRITE: Inner / Initial Digest [31:0] for SHA-1 [127:96] for SHA-2 / HMAC Key [415:384] for HMAC key proc READ: Intermediate / Inner Digest [31:0] for SHA-1 [127:96] for SHA-2 / Result Digest/MAC [31:0] for SHA-1 [95:64] for SHA-2 224 [127:96] for SHA-2 256.
  [31:0] DATA
0x1034 HSM_SHA_P_IDIGEST_F — WRITE: Inner / Initial Digest [95:64] for SHA-2 / HMAC Key [447:416] for HMAC key proc READ: Intermediate / Inner Digest [95:64] for SHA-2 / Result Digest/MAC [63:32] for SHA-2 224 [95:64] for SHA-2 256.
  [31:0] DATA
0x1038 HSM_SHA_P_IDIGEST_G — WRITE: Inner / Initial Digest [63:32] for SHA-2 / HMAC Key [479:448] for HMAC key proc READ: Intermediate / Inner Digest [63:32] for SHA-2 / Result Digest/MAC [31:0] for SHA-2 224 [63:32] for SHA-2 256.
  [31:0] DATA
0x103C HSM_SHA_P_IDIGEST_H — WRITE: Inner / Initial Digest [31:0] for SHA-2 / HMAC Key [511:480] for HMAC key proc READ: Intermediate / Inner Digest [31:0] for SHA-2 / Result Digest/MAC [31:0] for SHA-2 256.
  [31:0] DATA
0x1040 HSM_SHA_P_DIGEST_COUNT — WRITE: Initial Digest Count ([31:6] only [5:0] assumed 0) READ: Result / IntermediateDigest Count The initial digest byte count for hash/HMAC continue operations (HMAC Key Processing = 0 and Use Algorithm Constants = 0) on the Secure World must be written to this register prior to starting the operation by writing to S_HASH_MODE. When either HMAC Key Processing is 1 or Use Algorithm Constants is 1 this register does not need to be written it will be overwritten with 64 (1 hash block of key XOR ipad) or 0 respectively automatically. When starting a HMAC operation from pre-computes (HMAC Key Processing is 0) then the value 64 must be written here to compensate for the appended key XOR ipad block. Note that the value written should always be a 64 byte multiple the lower 6 bits written are ignored. The updated digest byte count (initial digest byte count + bytes processed) can be read from this register when the status register indicates that the operation is done or suspended due to a context switch request or when a Secure World context out DMA is requested. In Advanced DMA mode when not suspended with a partial result reading the SHA_P_DIGEST_COUNT register triggers the Hash/HMAC Engine to start the next context input DMA. Therefore reading the SHA_P_DIGEST_COUNT register should always be the last context-read action if not suspended with a partial result (i.e. PartHashReady interrupt not pending).
  [31:0] DATA
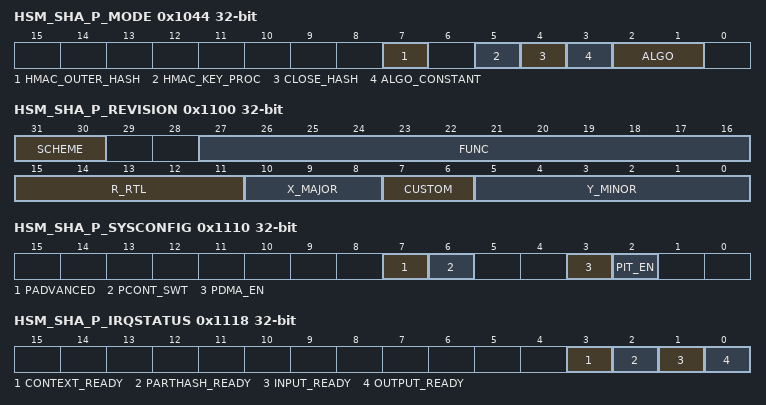
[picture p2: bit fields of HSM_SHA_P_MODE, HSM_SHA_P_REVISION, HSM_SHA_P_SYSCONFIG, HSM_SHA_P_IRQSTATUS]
0x1044 HSM_SHA_P_MODE — Register SHA_MODE.
  fields as HSM_SHA_S_MODE
0x1048 HSM_SHA_P_LENGTH — WRITE: Block Length / Remaining Byte Count (bytes) READ: Remaining Byte Count. The value programmed MUST be a 64-byte multiple if Close Hash is set to 0. This register is also the trigger to start processing: once this register is written the core will commence requesting input data via DMA or IRQ (if programmed length > 0) and start processing. The remaining byte count for the active operation can be read from this register when the interrupt status register indicates that the operation is suspended due to a context switch request.
  [31:0] DATA
{0x1080+4i} HSM_SHA_P_DATA{i}_IN wo (i=0..9) — Data input message {i}
  [31:0] DATA{i}_IN — data
{0x1080+4i} HSM_SHA_P_DATA{i}_IN wo (i=10..15) — Data input message {i}.
  [31:0] DATA{i}_IN — data
0x1100 HSM_SHA_P_REVISION ro — Register SHA_REV.
  fields as HSM_SHA_S_REVISION
0x1110 HSM_SHA_P_SYSCONFIG — Register SHA_SYSCONFIG.
  fields as HSM_SHA_S_SYSCONFIG
0x1114 HSM_SHA_P_SYSSTATUS — Register SHA_SYSSTATUS.
  [0] RESETDONE — data
0x1118 HSM_SHA_P_IRQSTATUS ro — Register SHA_IRQSTATUS.
  fields as HSM_SHA_S_IRQSTATUS
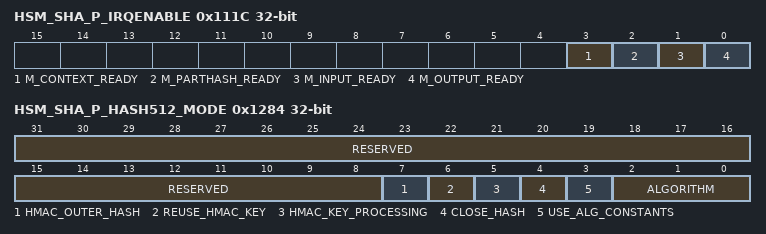
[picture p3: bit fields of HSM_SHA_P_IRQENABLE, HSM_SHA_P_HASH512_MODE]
0x111C HSM_SHA_P_IRQENABLE — Register SHA_IRQENABLE. The SHA_P_IRQENABLE register contains an enable bit for each unique interrupt for the public side. An interrupt is enabled when both the global enable in SHA_P_SYSCONFIG (PIT_en) and the bit in this register are both set to 1. An interrupt that is enabled is propagated to the SINTREQUEST_P output. Please note that the dedicated partial hash output (SINTREQUEST_PART_P) is not affected by this register it is only affected by the global enable SHA_P_SYSCONFIG (PIT_en).
  fields as HSM_SHA_S_IRQENABLE
0x1200 HSM_SHA_P_HASH512_ODIGEST_A — Public World Outer SHA-512 Digest .
  fields as HSM_SHA_S_HASH512_ODIGEST_A
0x1204 HSM_SHA_P_HASH512_ODIGEST_B — Public World Outer SHA-512 Digest .
  fields as HSM_SHA_S_HASH512_ODIGEST_B
0x1208 HSM_SHA_P_HASH512_ODIGEST_C — Public World Outer SHA-512 Digest .
  fields as HSM_SHA_S_HASH512_ODIGEST_C
0x120C HSM_SHA_P_HASH512_ODIGEST_D — Public World Outer SHA-512 Digest .
  fields as HSM_SHA_S_HASH512_ODIGEST_D
0x1210 HSM_SHA_P_HASH512_ODIGEST_E — Public World Outer SHA-512 Digest .
  fields as HSM_SHA_S_HASH512_ODIGEST_E
0x1214 HSM_SHA_P_HASH512_ODIGEST_F — Public World Outer SHA-512 Digest .
  fields as HSM_SHA_S_HASH512_ODIGEST_F
0x1218 HSM_SHA_P_HASH512_ODIGEST_G — Public World Outer SHA-512 Digest .
  fields as HSM_SHA_S_HASH512_ODIGEST_G
0x121C HSM_SHA_P_HASH512_ODIGEST_H — Public World Outer SHA-512 Digest .
  fields as HSM_SHA_S_HASH512_ODIGEST_H
0x1220 HSM_SHA_P_HASH512_ODIGEST_I — Public World Outer SHA-512 Digest .
  fields as HSM_SHA_S_HASH512_ODIGEST_I
0x1224 HSM_SHA_P_HASH512_ODIGEST_J — Public World Outer SHA-512 Digest .
  fields as HSM_SHA_S_HASH512_ODIGEST_J
0x1228 HSM_SHA_P_HASH512_ODIGEST_K — Public World Outer SHA-512 Digest .
  fields as HSM_SHA_S_HASH512_ODIGEST_K
0x122C HSM_SHA_P_HASH512_ODIGEST_L — Public World Outer SHA-512 Digest .
  fields as HSM_SHA_S_HASH512_ODIGEST_L
0x1230 HSM_SHA_P_HASH512_ODIGEST_M — Public World Outer SHA-512 Digest .
  fields as HSM_SHA_S_HASH512_ODIGEST_M
0x1234 HSM_SHA_P_HASH512_ODIGEST_N — Public World Outer SHA-512 Digest .
  fields as HSM_SHA_S_HASH512_ODIGEST_N
0x1238 HSM_SHA_P_HASH512_ODIGEST_O — Public World Outer SHA-512 Digest .
  fields as HSM_SHA_S_HASH512_ODIGEST_O
0x123C HSM_SHA_P_HASH512_ODIGEST_P — Public World Outer SHA-512 Digest .
  fields as HSM_SHA_S_HASH512_ODIGEST_P
0x1240 HSM_SHA_P_HASH512_IDIGEST_A — Public World Inner SHA-512 Digest .
  fields as HSM_SHA_S_HASH512_IDIGEST_A
0x1244 HSM_SHA_P_HASH512_IDIGEST_B — Public World Inner SHA-512 Digest .
  fields as HSM_SHA_S_HASH512_IDIGEST_B
0x1248 HSM_SHA_P_HASH512_IDIGEST_C — Public World Inner SHA-512 Digest .
  fields as HSM_SHA_S_HASH512_IDIGEST_C
0x124C HSM_SHA_P_HASH512_IDIGEST_D — Public World Inner SHA-512 Digest .
  fields as HSM_SHA_S_HASH512_IDIGEST_D
0x1250 HSM_SHA_P_HASH512_IDIGEST_E — Public World Inner SHA-512 Digest .
  fields as HSM_SHA_S_HASH512_IDIGEST_E
0x1254 HSM_SHA_P_HASH512_IDIGEST_F — Public World Inner SHA-512 Digest .
  fields as HSM_SHA_S_HASH512_IDIGEST_F
0x1258 HSM_SHA_P_HASH512_IDIGEST_G — Public World Inner SHA-512 Digest .
  fields as HSM_SHA_S_HASH512_IDIGEST_G
0x125C HSM_SHA_P_HASH512_IDIGEST_H — Public World Inner SHA-512 Digest .
  fields as HSM_SHA_S_HASH512_IDIGEST_H
0x1260 HSM_SHA_P_HASH512_IDIGEST_I — Public World Inner SHA-512 Digest .
  fields as HSM_SHA_S_HASH512_IDIGEST_I
0x1264 HSM_SHA_P_HASH512_IDIGEST_J — Public World Inner SHA-512 Digest .
  fields as HSM_SHA_S_HASH512_IDIGEST_J
0x1268 HSM_SHA_P_HASH512_IDIGEST_K — Public World Inner SHA-512 Digest .
  fields as HSM_SHA_S_HASH512_IDIGEST_K
0x126C HSM_SHA_P_HASH512_IDIGEST_L — Public World Inner SHA-512 Digest .
  fields as HSM_SHA_S_HASH512_IDIGEST_L
0x1270 HSM_SHA_P_HASH512_IDIGEST_M — Public World Inner SHA-512 Digest .
  fields as HSM_SHA_S_HASH512_IDIGEST_M
0x1274 HSM_SHA_P_HASH512_IDIGEST_N — Public World Inner SHA-512 Digest .
  fields as HSM_SHA_S_HASH512_IDIGEST_N
0x1278 HSM_SHA_P_HASH512_IDIGEST_O — Public World Inner SHA-512 Digest .
  fields as HSM_SHA_S_HASH512_IDIGEST_O
0x127C HSM_SHA_P_HASH512_IDIGEST_P — Public World Inner SHA-512 Digest .
  fields as HSM_SHA_S_HASH512_IDIGEST_P
0x1280 HSM_SHA_P_HASH512_DIGEST_COUNT — Public World SHA-512 Digest Count .
  fields as HSM_SHA_S_HASH512_DIGEST_COUNT
0x1284 HSM_SHA_P_HASH512_MODE access per field — Public World SHA-512 Hash Mode.
  fields as HSM_SHA_S_HASH512_MODE
0x1288 HSM_SHA_P_HASH512_LENGTH — Public World SHA-512 Block Length .
  fields as HSM_SHA_S_HASH512_LENGTH
